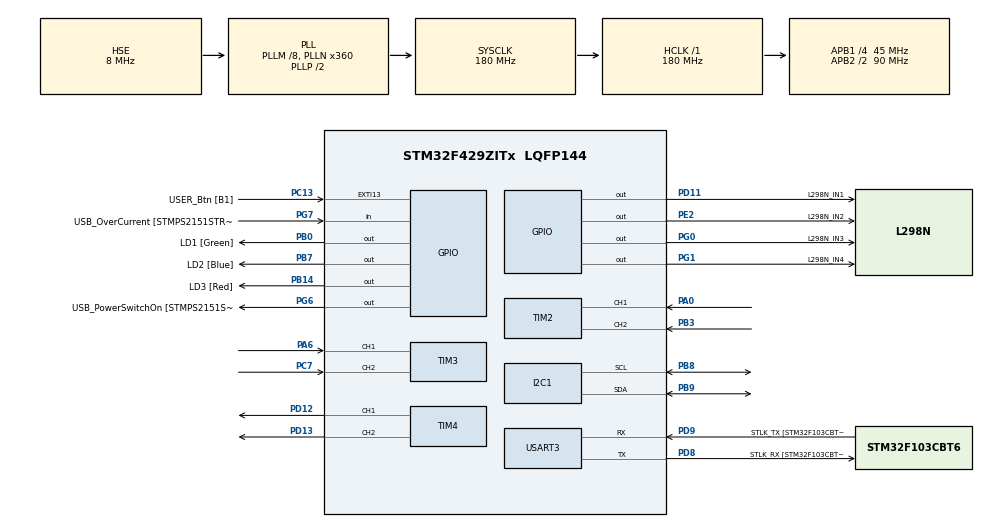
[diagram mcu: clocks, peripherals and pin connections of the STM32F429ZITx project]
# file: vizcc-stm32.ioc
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Dma.I2C1_RX.2.Direction=DMA_PERIPH_TO_MEMORY
Dma.I2C1_RX.2.FIFOMode=DMA_FIFOMODE_DISABLE
Dma.I2C1_RX.2.Instance=DMA1_Stream0
Dma.I2C1_RX.2.MemDataAlignment=DMA_MDATAALIGN_BYTE
Dma.I2C1_RX.2.MemInc=DMA_MINC_ENABLE
Dma.I2C1_RX.2.Mode=DMA_NORMAL
Dma.I2C1_RX.2.PeriphDataAlignment=DMA_PDATAALIGN_BYTE
Dma.I2C1_RX.2.PeriphInc=DMA_PINC_DISABLE
Dma.I2C1_RX.2.Priority=DMA_PRIORITY_LOW
Dma.Request0=USART3_RX
Dma.Request1=USART3_TX
Dma.Request2=I2C1_RX
Dma.USART3_RX.0.Direction=DMA_PERIPH_TO_MEMORY
Dma.USART3_RX.0.FIFOMode=DMA_FIFOMODE_DISABLE
Dma.USART3_RX.0.Instance=DMA1_Stream1
Dma.USART3_RX.0.MemDataAlignment=DMA_MDATAALIGN_BYTE
Dma.USART3_RX.0.MemInc=DMA_MINC_ENABLE
Dma.USART3_RX.0.Mode=DMA_CIRCULAR
Dma.USART3_RX.0.PeriphDataAlignment=DMA_PDATAALIGN_BYTE
Dma.USART3_RX.0.PeriphInc=DMA_PINC_DISABLE
Dma.USART3_RX.0.Priority=DMA_PRIORITY_VERY_HIGH
Dma.USART3_TX.1.Direction=DMA_MEMORY_TO_PERIPH
Dma.USART3_TX.1.FIFOMode=DMA_FIFOMODE_DISABLE
Dma.USART3_TX.1.Instance=DMA1_Stream3
Dma.USART3_TX.1.MemDataAlignment=DMA_MDATAALIGN_BYTE
Dma.USART3_TX.1.MemInc=DMA_MINC_ENABLE
Dma.USART3_TX.1.Mode=DMA_NORMAL
Dma.USART3_TX.1.PeriphDataAlignment=DMA_PDATAALIGN_BYTE
Dma.USART3_TX.1.PeriphInc=DMA_PINC_DISABLE
Dma.USART3_TX.1.Priority=DMA_PRIORITY_VERY_HIGH
FREERTOS.Tasks01=defaultTask,24,128,StartDefaultTask,Default,NULL,Static,defaultTaskBuffer,defaultTaskControlBlock
I2C1.I2C_Mode=I2C_Fast
Mcu.Family=STM32F4
Mcu.Name=STM32F429ZITx
Mcu.Package=LQFP144
NVIC.DMA1_Stream0_IRQn=true\:5\:0\:false\:false\:true\:true\:false\:true\:true
NVIC.DMA1_Stream1_IRQn=true\:5\:0\:false\:false\:true\:true\:false\:true\:true
NVIC.DMA1_Stream3_IRQn=true\:5\:0\:false\:false\:true\:true\:false\:true\:true
NVIC.PriorityGroup=NVIC_PRIORITYGROUP_4
NVIC.TIM1_UP_TIM10_IRQn=true\:15\:0\:false\:false\:true\:false\:false\:true\:true
NVIC.TimeBase=TIM1_UP_TIM10_IRQn
NVIC.TimeBaseIP=TIM1
NVIC.USART3_IRQn=true\:5\:0\:false\:false\:true\:true\:true\:true\:true
PA0/WKUP.Signal=S_TIM2_CH1_ETR
PA1.GPIO_Label=RMII_REF_CLK [LAN8742A-CZ-TR_REFCLK0]
PA1.Signal=ETH_REF_CLK
PA10.GPIO_Label=USB_ID
PA10.Signal=USB_OTG_FS_ID
PA11.GPIO_Label=USB_DM
PA11.Signal=USB_OTG_FS_DM
PA12.GPIO_Label=USB_DP
PA12.Signal=USB_OTG_FS_DP
PA13.GPIO_Label=TMS
PA13.Signal=SYS_JTMS-SWDIO
PA14.GPIO_Label=TCK
PA14.Signal=SYS_JTCK-SWCLK
PA2.GPIO_Label=RMII_MDIO [LAN8742A-CZ-TR_MDIO]
PA2.Signal=ETH_MDIO
PA6.Signal=S_TIM3_CH1
PA7.GPIO_Label=RMII_CRS_DV [LAN8742A-CZ-TR_CRS_DV]
PA7.Signal=ETH_CRS_DV
PA8.GPIO_Label=USB_SOF [TP1]
PA8.Signal=USB_OTG_FS_SOF
PA9.GPIO_Label=USB_VBUS
PA9.Signal=USB_OTG_FS_VBUS
PB0.GPIO_Label=LD1 [Green]
PB0.Signal=GPIO_Output
PB13.GPIO_Label=RMII_TXD1 [LAN8742A-CZ-TR_TXD1]
PB13.Signal=ETH_TXD1
PB14.GPIO_Label=LD3 [Red]
PB14.Signal=GPIO_Output
PB3.Signal=S_TIM2_CH2
PB7.GPIO_Label=LD2 [Blue]
PB7.Signal=GPIO_Output
PB8.Mode=I2C
PB8.Signal=I2C1_SCL
PB9.Mode=I2C
PB9.Signal=I2C1_SDA
PC1.GPIO_Label=RMII_MDC [LAN8742A-CZ-TR_MDC]
PC1.Signal=ETH_MDC
PC13.GPIO_Label=USER_Btn [B1]
PC13.Signal=GPXTI13
PC14/OSC32_IN.Signal=RCC_OSC32_IN
PC15/OSC32_OUT.Signal=RCC_OSC32_OUT
PC4.GPIO_Label=RMII_RXD0 [LAN8742A-CZ-TR_RXD0]
PC4.Signal=ETH_RXD0
PC5.GPIO_Label=RMII_RXD1 [LAN8742A-CZ-TR_RXD1]
PC5.Signal=ETH_RXD1
PC7.Signal=S_TIM3_CH2
PD11.GPIO_Label=L298N_IN1
PD11.Signal=GPIO_Output
PD12.Signal=S_TIM4_CH1
PD13.Signal=S_TIM4_CH2
PD8.GPIO_Label=STLK_RX [STM32F103CBT6_PA3]
PD8.Mode=Asynchronous
PD8.Signal=USART3_TX
PD9.GPIO_Label=STLK_TX [STM32F103CBT6_PA2]
PD9.Mode=Asynchronous
PD9.Signal=USART3_RX
PE2.GPIO_Label=L298N_IN2
PE2.Signal=GPIO_Output
PG0.GPIO_Label=L298N_IN3
PG0.Signal=GPIO_Output
PG1.GPIO_Label=L298N_IN4
PG1.Signal=GPIO_Output
PG11.GPIO_Label=RMII_TX_EN [LAN8742A-CZ-TR_TXEN]
PG11.Signal=ETH_TX_EN
PG13.GPIO_Label=RMII_TXD0 [LAN8742A-CZ-TR_TXD0]
PG13.Signal=ETH_TXD0
PG6.GPIO_Label=USB_PowerSwitchOn [STMPS2151STR_EN]
PG6.Signal=GPIO_Output
PG7.GPIO_Label=USB_OverCurrent [STMPS2151STR_FAULT]
PG7.Signal=GPIO_Input
PH0/OSC_IN.GPIO_Label=MCO [STM32F103CBT6_PA8]
PH0/OSC_IN.Mode=HSE-External-Oscillator
PH0/OSC_IN.Signal=RCC_OSC_IN
PH1/OSC_OUT.Mode=HSE-External-Oscillator
PH1/OSC_OUT.Signal=RCC_OSC_OUT
ProjectManager.HeapSize=0x200
ProjectManager.StackSize=0x400
ProjectManager.TargetToolchain=Makefile
RCC.48MHZClocksFreq_Value=90000000
RCC.AHBFreq_Value=180000000
RCC.APB1CLKDivider=RCC_HCLK_DIV4
RCC.APB1Freq_Value=45000000
RCC.APB1TimFreq_Value=90000000
RCC.APB2CLKDivider=RCC_HCLK_DIV2
RCC.APB2Freq_Value=90000000
RCC.APB2TimFreq_Value=180000000
RCC.CortexFreq_Value=180000000
RCC.HCLKFreq_Value=180000000
RCC.HSE_VALUE=8000000
RCC.HSI_VALUE=16000000
RCC.LSE_VALUE=32768
RCC.PLLM=8
RCC.PLLMUL=RCC_PLL_MUL9
RCC.PLLN=360
RCC.PLLSourceVirtual=RCC_PLLSOURCE_HSE
RCC.PRESCALERUSB=RCC_USBCLKSOURCE_PLL_DIV1_5
RCC.SYSCLKFreq_VALUE=180000000
RCC.SYSCLKSource=RCC_SYSCLKSOURCE_PLLCLK
RCC.SYSCLKSourceVirtual=RCC_SYSCLKSOURCE_PLLCLK
RCC.USBFreq_Value=48000000
RCC.VCOOutputFreq_Value=360000000
SH.S_TIM2_CH1_ETR.0=TIM2_CH1,Encoder_Interface
SH.S_TIM2_CH2.0=TIM2_CH2,Encoder_Interface
SH.S_TIM3_CH1.0=TIM3_CH1,Encoder_Interface
SH.S_TIM3_CH2.0=TIM3_CH2,Encoder_Interface
SH.S_TIM4_CH1.0=TIM4_CH1,PWM Generation1 CH1
SH.S_TIM4_CH2.0=TIM4_CH2,PWM Generation2 CH2
TIM2.AutoReloadPreload=TIM_AUTORELOAD_PRELOAD_ENABLE
TIM2.IC1Filter=10
TIM2.IC2Filter=10
TIM3.AutoReloadPreload=TIM_AUTORELOAD_PRELOAD_ENABLE
TIM4.AutoReloadPreload=TIM_AUTORELOAD_PRELOAD_ENABLE
TIM4.Channel-PWM\ Generation1\ CH1=TIM_CHANNEL_1
TIM4.Channel-PWM\ Generation2\ CH2=TIM_CHANNEL_2
USART3.VirtualMode=VM_ASYNC
VP_FREERTOS_VS_CMSIS_V2.Mode=CMSIS_V2
VP_SYS_VS_tim1.Mode=TIM1
VP_TIM4_VS_ClockSourceINT.Mode=Internal
board=NUCLEO-F429ZI

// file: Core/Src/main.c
/* USER CODE BEGIN Header */
/**
 ******************************************************************************
 * @file           : main.c
 * @brief          : Main program body
 ******************************************************************************
 * @attention
 *
 * Copyright (c) 2024 STMicroelectronics.
 * All rights reserved.
 *
 * This software is licensed under terms that can be found in the LICENSE file
 * in the root directory of this software component.
 * If no LICENSE file comes with this software, it is provided AS-IS.
 *
 ******************************************************************************
 */
/* USER CODE END Header */
#include "main.h"
#include "cmsis_os.h"
#include "dma.h"
#include "gpio.h"
#include "i2c.h"
#include "tim.h"
#include "usart.h"

/* USER CODE BEGIN Includes */
#include "uros_layer.h"
#include "vizcc_app.h"
/* USER CODE END Includes */

void SystemClock_Config(void);
void MX_FREERTOS_Init(void);

int main(void) {

    /* MCU Configuration--------------------------------------------------------*/

    /* Reset of all peripherals, Initializes the Flash interface and the Systick. */
    HAL_Init();

    /* Configure the system clock */
    SystemClock_Config();

    /* Initialize all configured peripherals */
    MX_GPIO_Init();
    MX_DMA_Init();
    MX_USART3_UART_Init();
    MX_TIM2_Init();
    MX_TIM4_Init();
    MX_TIM3_Init();
    MX_I2C1_Init();
    /* USER CODE BEGIN 2 */
    vizcc_app_init();

    /* USER CODE END 2 */

    /* Init scheduler */
    osKernelInitialize(); /* Call init function for freertos objects (in freertos.c) */
    MX_FREERTOS_Init();

    /* Start scheduler */
    osKernelStart();

    /* We should never get here as control is now taken by the scheduler */
    /* Infinite loop */
    while (1) {

    }
}

void SystemClock_Config(void) {
    RCC_OscInitTypeDef RCC_OscInitStruct = {0};
    RCC_ClkInitTypeDef RCC_ClkInitStruct = {0};

    /** Configure the main internal regulator output voltage
     */
    __HAL_RCC_PWR_CLK_ENABLE();
    __HAL_PWR_VOLTAGESCALING_CONFIG(PWR_REGULATOR_VOLTAGE_SCALE1);

    /** Initializes the RCC Oscillators according to the specified parameters
     * in the RCC_OscInitTypeDef structure.
     */
    RCC_OscInitStruct.OscillatorType = RCC_OSCILLATORTYPE_HSE;
    RCC_OscInitStruct.HSEState = RCC_HSE_ON;
    RCC_OscInitStruct.PLL.PLLState = RCC_PLL_ON;
    RCC_OscInitStruct.PLL.PLLSource = RCC_PLLSOURCE_HSE;
    RCC_OscInitStruct.PLL.PLLM = 8;
    RCC_OscInitStruct.PLL.PLLN = 360;
    RCC_OscInitStruct.PLL.PLLP = RCC_PLLP_DIV2;
    RCC_OscInitStruct.PLL.PLLQ = 4;
    if (HAL_RCC_OscConfig(&RCC_OscInitStruct) != HAL_OK) {
        Error_Handler();
    }

    /** Activate the Over-Drive mode
     */
    if (HAL_PWREx_EnableOverDrive() != HAL_OK) {
        Error_Handler();
    }

    /** Initializes the CPU, AHB and APB buses clocks
     */
    RCC_ClkInitStruct.ClockType =
        RCC_CLOCKTYPE_HCLK | RCC_CLOCKTYPE_SYSCLK | RCC_CLOCKTYPE_PCLK1 | RCC_CLOCKTYPE_PCLK2;
    RCC_ClkInitStruct.SYSCLKSource = RCC_SYSCLKSOURCE_PLLCLK;
    RCC_ClkInitStruct.AHBCLKDivider = RCC_SYSCLK_DIV1;
    RCC_ClkInitStruct.APB1CLKDivider = RCC_HCLK_DIV4;
    RCC_ClkInitStruct.APB2CLKDivider = RCC_HCLK_DIV2;

    if (HAL_RCC_ClockConfig(&RCC_ClkInitStruct, FLASH_LATENCY_5) != HAL_OK) {
        Error_Handler();
    }
}

void HAL_TIM_PeriodElapsedCallback(TIM_HandleTypeDef *htim) {
    if (htim->Instance == TIM1) {
        HAL_IncTick();
    }
}

void Error_Handler(void) {
    __disable_irq();
    while (1) {
    }
}

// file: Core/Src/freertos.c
/* USER CODE BEGIN Header */
/**
 ******************************************************************************
 * File Name          : freertos.c
 * Description        : Code for freertos applications
 ******************************************************************************
 * @attention
 *
 * Copyright (c) 2024 STMicroelectronics.
 * All rights reserved.
 *
 * This software is licensed under terms that can be found in the LICENSE file
 * in the root directory of this software component.
 * If no LICENSE file comes with this software, it is provided AS-IS.
 *
 ******************************************************************************
 */
/* USER CODE END Header */

#include "FreeRTOS.h"
#include "cmsis_os.h"
#include "main.h"
#include "task.h"

/* USER CODE BEGIN Includes */
#include <stdint.h>

/* USER CODE END Includes */

typedef StaticTask_t osStaticThreadDef_t;

/* Definitions for defaultTask */
osThreadId_t defaultTaskHandle;
uint32_t defaultTaskBuffer[128];
osStaticThreadDef_t defaultTaskControlBlock;
const osThreadAttr_t defaultTask_attributes = {
    .name = "defaultTask",
    .cb_mem = &defaultTaskControlBlock,
    .cb_size = sizeof(defaultTaskControlBlock),
    .stack_mem = &defaultTaskBuffer[0],
    .stack_size = sizeof(defaultTaskBuffer),
    .priority = (osPriority_t)osPriorityNormal,
};

void StartDefaultTask(void *argument);

void MX_FREERTOS_Init(void); /* (MISRA C 2004 rule 8.1) */

void MX_FREERTOS_Init(void) {
    /* USER CODE BEGIN Init */
    defaultTaskHandle = osThreadNew(StartDefaultTask, NULL, &defaultTask_attributes);

    /* USER CODE END Init */
    /* USER CODE BEGIN Header */
    /**
     ******************************************************************************
     * File Name          : freertos.c
     * Description        : Code for freertos applications
     ******************************************************************************
     * @attention
     *
     * Copyright (c) 2024 STMicroelectronics.
     * All rights reserved.
     *
     * This software is licensed under terms that can be found in the LICENSE file
     * in the root directory of this software component.
     * If no LICENSE file comes with this software, it is provided AS-IS.
     *
     ******************************************************************************
     */
    /* USER CODE END Header */

    /**
     * @}
     */

    /**
     * @}
     */
}

void StartDefaultTask(void *argument) {
    /* USER CODE BEGIN StartDefaultTask */

    /* Infinite loop */
    for (;;) {
        osDelay(500);
    }
    /* USER CODE END StartDefaultTask */
}
